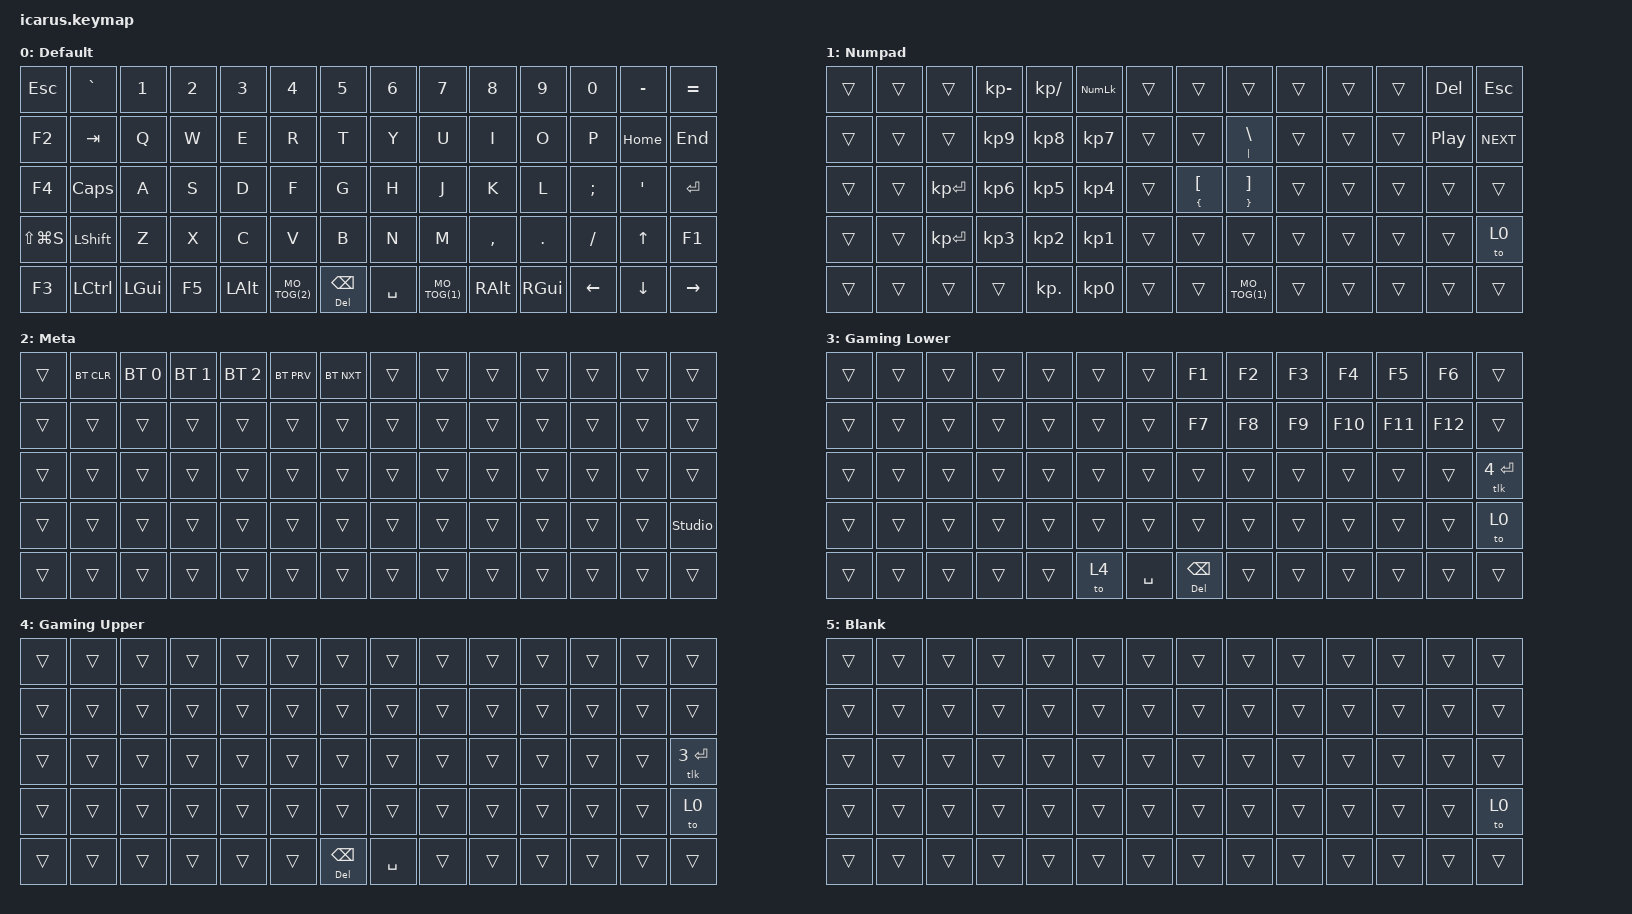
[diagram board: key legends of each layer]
#include <behaviors.dtsi>
#include <dt-bindings/zmk/keys.h>
#include <dt-bindings/zmk/bt.h>

#define MO_TOG(layer) &mo_tog layer layer

/ {
    behaviors {
        mo_tog: behavior_mo_tog {
            compatible = "zmk,behavior-hold-tap";
            #binding-cells = <2>;
            flavor = "hold-preferred";
            tapping-term-ms = <120>;
            bindings = <&mo>, <&tog>;
        };
        mt: mod_tap {
            compatible = "zmk,behavior-hold-tap";
            #binding-cells = <2>;
            flavor = "hold-preferred";
            tapping-term-ms = <120>;
            quick-tap-ms = <150>;
            bindings = <&kp>, <&kp>;
            display-name = "Mod-Tap";
        };
    };

    macros {
        tlk: to_layer_key {
            compatible = "zmk,behavior-macro-two-param";
            #binding-cells = <2>;
            bindings
                = <&macro_param_1to1>
                , <&macro_tap &to MACRO_PLACEHOLDER>
                , <&macro_param_2to1>
                , <&macro_tap &kp MACRO_PLACEHOLDER>
                ;
        };
    };

    keymap {
        compatible = "zmk,keymap";

        default_layer {
            display-name = "Default";
            bindings = <
                // 5x7 matrix on both sides, standard QWERTY layout for now. Placeholders are F keys for now.
                &kp ESC         &kp GRAVE  &kp N1   &kp N2   &kp N3   &kp N4     &kp N5            &kp N6    &kp N7       &kp N8    &kp N9   &kp N0    &kp MINUS  &kp EQUAL
                &kp F2          &kp TAB    &kp Q    &kp W    &kp E    &kp R      &kp T             &kp Y     &kp U        &kp I     &kp O    &kp P     &kp HOME   &kp END
                &kp F4          &kp CAPS   &kp A    &kp S    &kp D    &kp F      &kp G             &kp H     &kp J        &kp K     &kp L    &kp SEMI  &kp APOS   &kp ENTER
                &kp LS(LG(S))   &kp LSHIFT &kp Z    &kp X    &kp C    &kp V      &kp B             &kp N     &kp M        &kp COMMA &kp DOT  &kp SLASH &kp UP     &kp F1
                &kp F3          &kp LCTRL  &kp LGUI &kp F5   &kp LALT MO_TOG(2)  &mt DEL BSPC      &kp SPACE MO_TOG(1)    &kp RALT  &kp RGUI &kp LEFT  &kp DOWN   &kp RIGHT
            >;
        };

        special_keys {
            display-name = "Numpad";
            bindings = <
                // special keys, numpad, etc.
                &trans &trans &trans       &kp KP_MINUS &kp KP_SLASH &kp KP_NUM &trans        &trans        &trans        &trans &trans &trans &kp DEL  &kp ESC
                &trans &trans &trans       &kp KP_N9    &kp KP_N8    &kp KP_N7  &trans        &trans        &mt PIPE BSLH &trans &trans &trans &kp C_PP &kp C_NEXT
                &trans &trans &kp KP_ENTER &kp KP_N6    &kp KP_N5    &kp KP_N4  &trans        &mt LBRC LBKT &mt RBRC RBKT &trans &trans &trans &trans   &trans
                &trans &trans &kp KP_ENTER &kp KP_N3    &kp KP_N2    &kp KP_N1  &trans        &trans        &trans        &trans &trans &trans &trans   &to 0
                &trans &trans &trans       &trans       &kp KP_DOT   &kp KP_N0  &trans        &trans        MO_TOG(1)     &trans &trans &trans &trans   &trans
            >;
        };

        meta_keys {
            display-name = "Meta";
            bindings = <
                // keyboard meta keys
                &trans &bt BT_CLR &bt BT_SEL 0 &bt BT_SEL 1 &bt BT_SEL 2 &bt BT_PRV &bt BT_NXT        &trans &trans &trans &trans &trans &trans &trans
                &trans &trans     &trans       &trans       &trans       &trans     &trans            &trans &trans &trans &trans &trans &trans &trans
                &trans &trans     &trans       &trans       &trans       &trans     &trans            &trans &trans &trans &trans &trans &trans &trans
                &trans &trans     &trans       &trans       &trans       &trans     &trans            &trans &trans &trans &trans &trans &trans &studio_unlock
                &trans &trans     &trans       &trans       &trans       &trans     &trans            &trans &trans &trans &trans &trans &trans &trans
            >;
        };

        gaming_space {
            display-name = "Gaming Lower";
            bindings = <
                // blank layer for copy paste
                &trans &trans &trans &trans &trans &trans &trans        &kp F1        &kp F2 &kp F3  &kp F4  &kp F5  &kp F6  &trans
                &trans &trans &trans &trans &trans &trans &trans        &kp F7        &kp F8 &kp F9  &kp F10 &kp F11 &kp F12 &trans
                &trans &trans &trans &trans &trans &trans &trans        &trans        &trans &trans  &trans  &trans  &trans  &tlk 4 ENTER
                &trans &trans &trans &trans &trans &trans &trans        &trans        &trans &trans  &trans  &trans  &trans  &to 0
                &trans &trans &trans &trans &trans &to 4  &kp SPACE     &mt DEL BSPC  &trans &trans  &trans  &trans  &trans  &trans
            >;
        };

        gaming_space_2 {
            display-name = "Gaming Upper";
            bindings = <
                // blank layer for copy paste
                &trans &trans &trans &trans &trans &trans &trans           &trans    &trans &trans &trans &trans &trans &trans
                &trans &trans &trans &trans &trans &trans &trans           &trans    &trans &trans &trans &trans &trans &trans
                &trans &trans &trans &trans &trans &trans &trans           &trans    &trans &trans &trans &trans &trans &tlk 3 ENTER
                &trans &trans &trans &trans &trans &trans &trans           &trans    &trans &trans &trans &trans &trans &to 0
                &trans &trans &trans &trans &trans &trans &mt DEL BSPC     &kp SPACE &trans &trans &trans &trans &trans &trans
            >;
        };
        blank_layer {
            display-name = "Blank";
            bindings = <
                // blank layer for copy paste
                &trans &trans &trans &trans &trans &trans &trans        &trans &trans &trans &trans &trans &trans &trans
                &trans &trans &trans &trans &trans &trans &trans        &trans &trans &trans &trans &trans &trans &trans
                &trans &trans &trans &trans &trans &trans &trans        &trans &trans &trans &trans &trans &trans &trans
                &trans &trans &trans &trans &trans &trans &trans        &trans &trans &trans &trans &trans &trans &to 0
                &trans &trans &trans &trans &trans &trans &trans        &trans &trans &trans &trans &trans &trans &trans
            >;
        };
    };
};
